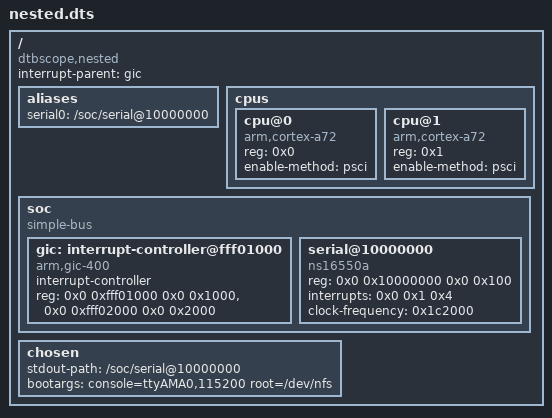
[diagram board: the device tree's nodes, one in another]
/dts-v1/;

/ {
	compatible = "dtbscope,nested";
	#address-cells = <2>;
	#size-cells = <2>;
	interrupt-parent = <&gic>;

	aliases {
		serial0 = "/soc/serial@10000000";
	};

	cpus {
		#address-cells = <1>;
		#size-cells = <0>;

		cpu@0 {
			device_type = "cpu";
			compatible = "arm,cortex-a72";
			reg = <0x0>;
			enable-method = "psci";
		};

		cpu@1 {
			device_type = "cpu";
			compatible = "arm,cortex-a72";
			reg = <0x1>;
			enable-method = "psci";
		};
	};

	soc {
		compatible = "simple-bus";
		#address-cells = <2>;
		#size-cells = <2>;
		ranges;

		gic: interrupt-controller@fff01000 {
			compatible = "arm,gic-400";
			#interrupt-cells = <3>;
			interrupt-controller;
			reg = <0x0 0xfff01000 0x0 0x1000>,
			      <0x0 0xfff02000 0x0 0x2000>;
		};

		serial@10000000 {
			compatible = "ns16550a";
			reg = <0x0 0x10000000 0x0 0x100>;
			interrupts = <0x0 0x1 0x4>;
			clock-frequency = <0x1c2000>;
		};
	};

	chosen {
		stdout-path = "/soc/serial@10000000";
		bootargs = "console=ttyAMA0,115200 root=/dev/nfs";
	};
};
